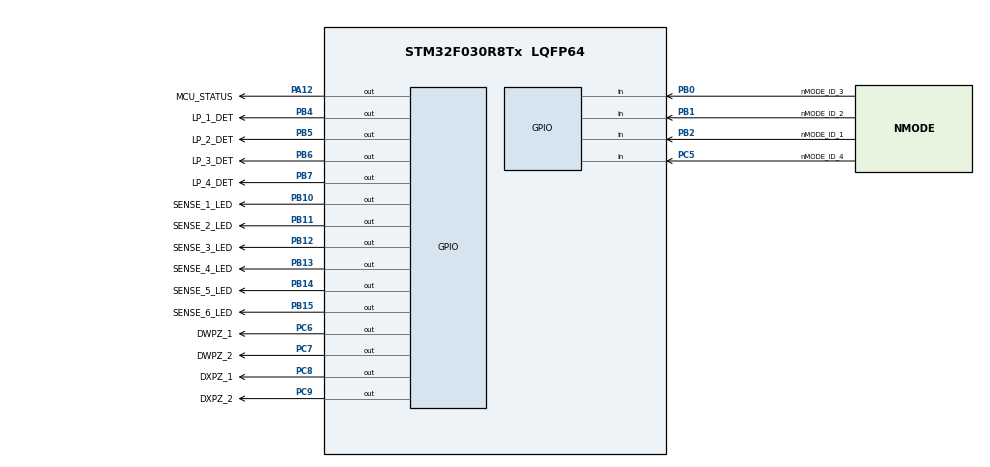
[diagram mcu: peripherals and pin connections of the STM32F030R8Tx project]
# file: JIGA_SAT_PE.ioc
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Mcu.Family=STM32F0
Mcu.Name=STM32F030R8Tx
Mcu.Package=LQFP64
NVIC.TIM6_IRQn=true\:0\:0\:true\:false\:true\:true\:true\:true
PA12.GPIO_Label=MCU_STATUS
PA12.Signal=GPIO_Output
PA13.Mode=Serial_Wire
PA13.Signal=SYS_SWDIO
PA14.Mode=Serial_Wire
PA14.Signal=SYS_SWCLK
PB0.GPIO_Label=nMODE_ID_3
PB0.GPIO_PuPd=GPIO_PULLUP
PB0.Signal=GPIO_Input
PB1.GPIO_Label=nMODE_ID_2
PB1.GPIO_PuPd=GPIO_PULLUP
PB1.Signal=GPIO_Input
PB10.GPIO_Label=SENSE_1_LED
PB10.Signal=GPIO_Output
PB11.GPIO_Label=SENSE_2_LED
PB11.Signal=GPIO_Output
PB12.GPIO_Label=SENSE_3_LED
PB12.Signal=GPIO_Output
PB13.GPIO_Label=SENSE_4_LED
PB13.Signal=GPIO_Output
PB14.GPIO_Label=SENSE_5_LED
PB14.Signal=GPIO_Output
PB15.GPIO_Label=SENSE_6_LED
PB15.Signal=GPIO_Output
PB2.GPIO_Label=nMODE_ID_1
PB2.GPIO_PuPd=GPIO_PULLUP
PB2.Signal=GPIO_Input
PB4.GPIO_Label=LP_1_DET
PB4.Signal=GPIO_Output
PB5.GPIO_Label=LP_2_DET
PB5.Signal=GPIO_Output
PB6.GPIO_Label=LP_3_DET
PB6.Signal=GPIO_Output
PB7.GPIO_Label=LP_4_DET
PB7.Signal=GPIO_Output
PC5.GPIO_Label=nMODE_ID_4
PC5.GPIO_PuPd=GPIO_PULLUP
PC5.Signal=GPIO_Input
PC6.GPIO_Label=DWPZ_1
PC6.Signal=GPIO_Output
PC7.GPIO_Label=DWPZ_2
PC7.Signal=GPIO_Output
PC8.GPIO_Label=DXPZ_1
PC8.Signal=GPIO_Output
PC9.GPIO_Label=DXPZ_2
PC9.Signal=GPIO_Output
PF0-OSC_IN.Mode=HSE-External-Oscillator
PF0-OSC_IN.Signal=RCC_OSC_IN
PF1-OSC_OUT.Mode=HSE-External-Oscillator
PF1-OSC_OUT.Signal=RCC_OSC_OUT
ProjectManager.HeapSize=0x200
ProjectManager.StackSize=0x400
ProjectManager.TargetToolchain=STM32CubeIDE
RCC.AHBFreq_Value=48000000
RCC.APB1Freq_Value=48000000
RCC.APB1TimFreq_Value=48000000
RCC.HCLKFreq_Value=48000000
RCC.PLLMUL=RCC_PLL_MUL6
RCC.PLLSourceVirtual=RCC_PLLSOURCE_HSE
RCC.SYSCLKFreq_VALUE=48000000
RCC.SYSCLKSource=RCC_SYSCLKSOURCE_PLLCLK
TIM6.AutoReloadPreload=TIM_AUTORELOAD_PRELOAD_DISABLE
TIM6.Period=1
TIM6.Prescaler=47-1
VP_TIM6_VS_ClockSourceINT.Mode=Enable_Timer
board=custom

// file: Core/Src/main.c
/* USER CODE BEGIN Header */
/**
  ******************************************************************************
  * @file           : main.c
  * @brief          : Main program body
  ******************************************************************************
  * @attention
  *
  * Copyright (c) 2024 STMicroelectronics.
  * All rights reserved.
  *
  * This software is licensed under terms that can be found in the LICENSE file
  * in the root directory of this software component.
  * If no LICENSE file comes with this software, it is provided AS-IS.
  *
  ******************************************************************************
  */
/* USER CODE END Header */
#include "main.h"

/* USER CODE BEGIN Includes */

#include "sl.h"

/* USER CODE END Includes */

void SystemClock_Config(void);
static void MX_GPIO_Init(void);
static void MX_TIM6_Init(void);

int main(void)
{
  /* USER CODE BEGIN 1 */
  //__enable_irq();

  /* USER CODE END 1 */

  /* MCU Configuration--------------------------------------------------------*/

  /* Reset of all peripherals, Initializes the Flash interface and the Systick. */
  LL_APB1_GRP2_EnableClock(LL_APB1_GRP2_PERIPH_SYSCFG);
  LL_APB1_GRP1_EnableClock(LL_APB1_GRP1_PERIPH_PWR);

  /* SysTick_IRQn interrupt configuration */
  NVIC_SetPriority(SysTick_IRQn, 2);

  /* Configure the system clock */
  SystemClock_Config();

  /* USER CODE BEGIN SysInit */
  LL_SYSTICK_EnableIT();
  /* USER CODE END SysInit */

  /* Initialize all configured peripherals */
  MX_GPIO_Init();
  MX_TIM6_Init();
  /* USER CODE BEGIN 2 */

  sl_init();

  /* USER CODE END 2 */

  /* Infinite loop */
  /* USER CODE BEGIN WHILE */
  while (1)
  {
    sl_update();
    /* USER CODE END WHILE */

  }
}

void SystemClock_Config(void)
{
  LL_FLASH_SetLatency(LL_FLASH_LATENCY_1);
  while(LL_FLASH_GetLatency() != LL_FLASH_LATENCY_1)
  {
  }
  LL_RCC_HSE_Enable();

   /* Wait till HSE is ready */
  while(LL_RCC_HSE_IsReady() != 1)
  {

  }
  LL_RCC_PLL_ConfigDomain_SYS(LL_RCC_PLLSOURCE_HSE_DIV_1, LL_RCC_PLL_MUL_6);
  LL_RCC_PLL_Enable();

   /* Wait till PLL is ready */
  while(LL_RCC_PLL_IsReady() != 1)
  {

  }
  LL_RCC_SetAHBPrescaler(LL_RCC_SYSCLK_DIV_1);
  LL_RCC_SetAPB1Prescaler(LL_RCC_APB1_DIV_1);
  LL_RCC_SetSysClkSource(LL_RCC_SYS_CLKSOURCE_PLL);

   /* Wait till System clock is ready */
  while(LL_RCC_GetSysClkSource() != LL_RCC_SYS_CLKSOURCE_STATUS_PLL)
  {

  }
  LL_Init1msTick(48000000);
  LL_SetSystemCoreClock(48000000);
}

static void MX_TIM6_Init(void)
{

  LL_TIM_InitTypeDef TIM_InitStruct = {0};

  /* Peripheral clock enable */
  LL_APB1_GRP1_EnableClock(LL_APB1_GRP1_PERIPH_TIM6);

  /* TIM6 interrupt Init */
  NVIC_SetPriority(TIM6_IRQn, 3);
  NVIC_EnableIRQ(TIM6_IRQn);

  TIM_InitStruct.Prescaler = 47-1;
  TIM_InitStruct.CounterMode = LL_TIM_COUNTERMODE_UP;
  TIM_InitStruct.Autoreload = 100;
  LL_TIM_Init(TIM6, &TIM_InitStruct);
  LL_TIM_DisableARRPreload(TIM6);
  /* USER CODE BEGIN TIM6_Init 2 */

  LL_TIM_EnableIT_UPDATE(TIM6);
  LL_TIM_EnableCounter(TIM6);

  /* USER CODE END TIM6_Init 2 */

}

static void MX_GPIO_Init(void)
{
  LL_GPIO_InitTypeDef GPIO_InitStruct = {0};

  /* GPIO Ports Clock Enable */
  LL_AHB1_GRP1_EnableClock(LL_AHB1_GRP1_PERIPH_GPIOF);
  LL_AHB1_GRP1_EnableClock(LL_AHB1_GRP1_PERIPH_GPIOC);
  LL_AHB1_GRP1_EnableClock(LL_AHB1_GRP1_PERIPH_GPIOB);
  LL_AHB1_GRP1_EnableClock(LL_AHB1_GRP1_PERIPH_GPIOA);

  /**/
  LL_GPIO_ResetOutputPin(SENSE_1_LED_GPIO_Port, SENSE_1_LED_Pin);

  /**/
  LL_GPIO_ResetOutputPin(SENSE_2_LED_GPIO_Port, SENSE_2_LED_Pin);

  /**/
  LL_GPIO_ResetOutputPin(SENSE_3_LED_GPIO_Port, SENSE_3_LED_Pin);

  /**/
  LL_GPIO_ResetOutputPin(SENSE_4_LED_GPIO_Port, SENSE_4_LED_Pin);

  /**/
  LL_GPIO_ResetOutputPin(SENSE_5_LED_GPIO_Port, SENSE_5_LED_Pin);

  /**/
  LL_GPIO_ResetOutputPin(SENSE_6_LED_GPIO_Port, SENSE_6_LED_Pin);

  /**/
  LL_GPIO_ResetOutputPin(DWPZ_1_GPIO_Port, DWPZ_1_Pin);

  /**/
  LL_GPIO_ResetOutputPin(DWPZ_2_GPIO_Port, DWPZ_2_Pin);

  /**/
  LL_GPIO_ResetOutputPin(DXPZ_1_GPIO_Port, DXPZ_1_Pin);

  /**/
  LL_GPIO_ResetOutputPin(DXPZ_2_GPIO_Port, DXPZ_2_Pin);

  /**/
  LL_GPIO_ResetOutputPin(MCU_STATUS_GPIO_Port, MCU_STATUS_Pin);

  /**/
  LL_GPIO_ResetOutputPin(LP_1_DET_GPIO_Port, LP_1_DET_Pin);

  /**/
  LL_GPIO_ResetOutputPin(LP_2_DET_GPIO_Port, LP_2_DET_Pin);

  /**/
  LL_GPIO_ResetOutputPin(LP_3_DET_GPIO_Port, LP_3_DET_Pin);

  /**/
  LL_GPIO_ResetOutputPin(LP_4_DET_GPIO_Port, LP_4_DET_Pin);

  /**/
  GPIO_InitStruct.Pin = nMODE_ID_4_Pin;
  GPIO_InitStruct.Mode = LL_GPIO_MODE_INPUT;
  GPIO_InitStruct.Pull = LL_GPIO_PULL_UP;
  LL_GPIO_Init(nMODE_ID_4_GPIO_Port, &GPIO_InitStruct);

  /**/
  GPIO_InitStruct.Pin = nMODE_ID_3_Pin;
  GPIO_InitStruct.Mode = LL_GPIO_MODE_INPUT;
  GPIO_InitStruct.Pull = LL_GPIO_PULL_UP;
  LL_GPIO_Init(nMODE_ID_3_GPIO_Port, &GPIO_InitStruct);

  /**/
  GPIO_InitStruct.Pin = nMODE_ID_2_Pin;
  GPIO_InitStruct.Mode = LL_GPIO_MODE_INPUT;
  GPIO_InitStruct.Pull = LL_GPIO_PULL_UP;
  LL_GPIO_Init(nMODE_ID_2_GPIO_Port, &GPIO_InitStruct);

  /**/
  GPIO_InitStruct.Pin = nMODE_ID_1_Pin;
  GPIO_InitStruct.Mode = LL_GPIO_MODE_INPUT;
  GPIO_InitStruct.Pull = LL_GPIO_PULL_UP;
  LL_GPIO_Init(nMODE_ID_1_GPIO_Port, &GPIO_InitStruct);

  /**/
  GPIO_InitStruct.Pin = SENSE_1_LED_Pin;
  GPIO_InitStruct.Mode = LL_GPIO_MODE_OUTPUT;
  GPIO_InitStruct.Speed = LL_GPIO_SPEED_FREQ_LOW;
  GPIO_InitStruct.OutputType = LL_GPIO_OUTPUT_PUSHPULL;
  GPIO_InitStruct.Pull = LL_GPIO_PULL_NO;
  LL_GPIO_Init(SENSE_1_LED_GPIO_Port, &GPIO_InitStruct);

  /**/
  GPIO_InitStruct.Pin = SENSE_2_LED_Pin;
  GPIO_InitStruct.Mode = LL_GPIO_MODE_OUTPUT;
  GPIO_InitStruct.Speed = LL_GPIO_SPEED_FREQ_LOW;
  GPIO_InitStruct.OutputType = LL_GPIO_OUTPUT_PUSHPULL;
  GPIO_InitStruct.Pull = LL_GPIO_PULL_NO;
  LL_GPIO_Init(SENSE_2_LED_GPIO_Port, &GPIO_InitStruct);

  /**/
  GPIO_InitStruct.Pin = SENSE_3_LED_Pin;
  GPIO_InitStruct.Mode = LL_GPIO_MODE_OUTPUT;
  GPIO_InitStruct.Speed = LL_GPIO_SPEED_FREQ_LOW;
  GPIO_InitStruct.OutputType = LL_GPIO_OUTPUT_PUSHPULL;
  GPIO_InitStruct.Pull = LL_GPIO_PULL_NO;
  LL_GPIO_Init(SENSE_3_LED_GPIO_Port, &GPIO_InitStruct);

  /**/
  GPIO_InitStruct.Pin = SENSE_4_LED_Pin;
  GPIO_InitStruct.Mode = LL_GPIO_MODE_OUTPUT;
  GPIO_InitStruct.Speed = LL_GPIO_SPEED_FREQ_LOW;
  GPIO_InitStruct.OutputType = LL_GPIO_OUTPUT_PUSHPULL;
  GPIO_InitStruct.Pull = LL_GPIO_PULL_NO;
  LL_GPIO_Init(SENSE_4_LED_GPIO_Port, &GPIO_InitStruct);

  /**/
  GPIO_InitStruct.Pin = SENSE_5_LED_Pin;
  GPIO_InitStruct.Mode = LL_GPIO_MODE_OUTPUT;
  GPIO_InitStruct.Speed = LL_GPIO_SPEED_FREQ_LOW;
  GPIO_InitStruct.OutputType = LL_GPIO_OUTPUT_PUSHPULL;
  GPIO_InitStruct.Pull = LL_GPIO_PULL_NO;
  LL_GPIO_Init(SENSE_5_LED_GPIO_Port, &GPIO_InitStruct);

  /**/
  GPIO_InitStruct.Pin = SENSE_6_LED_Pin;
  GPIO_InitStruct.Mode = LL_GPIO_MODE_OUTPUT;
  GPIO_InitStruct.Speed = LL_GPIO_SPEED_FREQ_LOW;
  GPIO_InitStruct.OutputType = LL_GPIO_OUTPUT_PUSHPULL;
  GPIO_InitStruct.Pull = LL_GPIO_PULL_NO;
  LL_GPIO_Init(SENSE_6_LED_GPIO_Port, &GPIO_InitStruct);

  /**/
  GPIO_InitStruct.Pin = DWPZ_1_Pin;
  GPIO_InitStruct.Mode = LL_GPIO_MODE_OUTPUT;
  GPIO_InitStruct.Speed = LL_GPIO_SPEED_FREQ_LOW;
  GPIO_InitStruct.OutputType = LL_GPIO_OUTPUT_PUSHPULL;
  GPIO_InitStruct.Pull = LL_GPIO_PULL_NO;
  LL_GPIO_Init(DWPZ_1_GPIO_Port, &GPIO_InitStruct);

  /**/
  GPIO_InitStruct.Pin = DWPZ_2_Pin;
  GPIO_InitStruct.Mode = LL_GPIO_MODE_OUTPUT;
  GPIO_InitStruct.Speed = LL_GPIO_SPEED_FREQ_LOW;
  GPIO_InitStruct.OutputType = LL_GPIO_OUTPUT_PUSHPULL;
  GPIO_InitStruct.Pull = LL_GPIO_PULL_NO;
  LL_GPIO_Init(DWPZ_2_GPIO_Port, &GPIO_InitStruct);

  /**/
  GPIO_InitStruct.Pin = DXPZ_1_Pin;
  GPIO_InitStruct.Mode = LL_GPIO_MODE_OUTPUT;
  GPIO_InitStruct.Speed = LL_GPIO_SPEED_FREQ_LOW;
  GPIO_InitStruct.OutputType = LL_GPIO_OUTPUT_PUSHPULL;
  GPIO_InitStruct.Pull = LL_GPIO_PULL_NO;
  LL_GPIO_Init(DXPZ_1_GPIO_Port, &GPIO_InitStruct);

  /**/
  GPIO_InitStruct.Pin = DXPZ_2_Pin;
  GPIO_InitStruct.Mode = LL_GPIO_MODE_OUTPUT;
  GPIO_InitStruct.Speed = LL_GPIO_SPEED_FREQ_LOW;
  GPIO_InitStruct.OutputType = LL_GPIO_OUTPUT_PUSHPULL;
  GPIO_InitStruct.Pull = LL_GPIO_PULL_NO;
  LL_GPIO_Init(DXPZ_2_GPIO_Port, &GPIO_InitStruct);

  /**/
  GPIO_InitStruct.Pin = MCU_STATUS_Pin;
  GPIO_InitStruct.Mode = LL_GPIO_MODE_OUTPUT;
  GPIO_InitStruct.Speed = LL_GPIO_SPEED_FREQ_LOW;
  GPIO_InitStruct.OutputType = LL_GPIO_OUTPUT_PUSHPULL;
  GPIO_InitStruct.Pull = LL_GPIO_PULL_NO;
  LL_GPIO_Init(MCU_STATUS_GPIO_Port, &GPIO_InitStruct);

  /**/
  GPIO_InitStruct.Pin = LP_1_DET_Pin;
  GPIO_InitStruct.Mode = LL_GPIO_MODE_OUTPUT;
  GPIO_InitStruct.Speed = LL_GPIO_SPEED_FREQ_LOW;
  GPIO_InitStruct.OutputType = LL_GPIO_OUTPUT_PUSHPULL;
  GPIO_InitStruct.Pull = LL_GPIO_PULL_NO;
  LL_GPIO_Init(LP_1_DET_GPIO_Port, &GPIO_InitStruct);

  /**/
  GPIO_InitStruct.Pin = LP_2_DET_Pin;
  GPIO_InitStruct.Mode = LL_GPIO_MODE_OUTPUT;
  GPIO_InitStruct.Speed = LL_GPIO_SPEED_FREQ_LOW;
  GPIO_InitStruct.OutputType = LL_GPIO_OUTPUT_PUSHPULL;
  GPIO_InitStruct.Pull = LL_GPIO_PULL_NO;
  LL_GPIO_Init(LP_2_DET_GPIO_Port, &GPIO_InitStruct);

  /**/
  GPIO_InitStruct.Pin = LP_3_DET_Pin;
  GPIO_InitStruct.Mode = LL_GPIO_MODE_OUTPUT;
  GPIO_InitStruct.Speed = LL_GPIO_SPEED_FREQ_LOW;
  GPIO_InitStruct.OutputType = LL_GPIO_OUTPUT_PUSHPULL;
  GPIO_InitStruct.Pull = LL_GPIO_PULL_NO;
  LL_GPIO_Init(LP_3_DET_GPIO_Port, &GPIO_InitStruct);

  /**/
  GPIO_InitStruct.Pin = LP_4_DET_Pin;
  GPIO_InitStruct.Mode = LL_GPIO_MODE_OUTPUT;
  GPIO_InitStruct.Speed = LL_GPIO_SPEED_FREQ_LOW;
  GPIO_InitStruct.OutputType = LL_GPIO_OUTPUT_PUSHPULL;
  GPIO_InitStruct.Pull = LL_GPIO_PULL_NO;
  LL_GPIO_Init(LP_4_DET_GPIO_Port, &GPIO_InitStruct);

}

void Error_Handler(void)
{
  __disable_irq();
  while (1)
  {
  }
}
